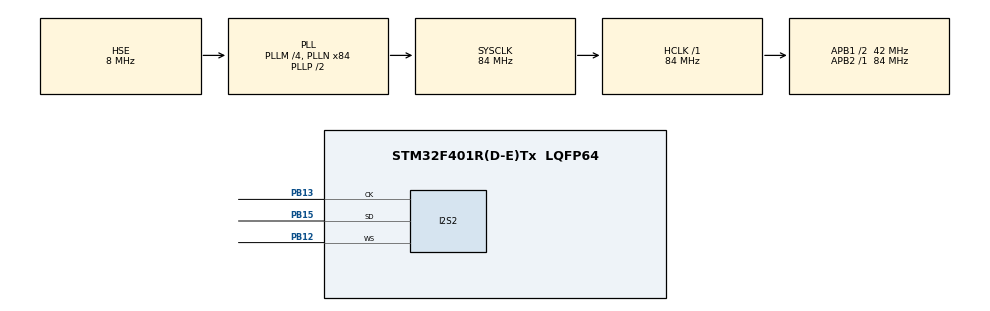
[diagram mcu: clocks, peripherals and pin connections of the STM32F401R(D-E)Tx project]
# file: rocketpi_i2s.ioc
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Dma.Request0=SPI2_TX
Dma.SPI2_TX.0.Direction=DMA_MEMORY_TO_PERIPH
Dma.SPI2_TX.0.FIFOMode=DMA_FIFOMODE_DISABLE
Dma.SPI2_TX.0.Instance=DMA1_Stream4
Dma.SPI2_TX.0.MemDataAlignment=DMA_MDATAALIGN_HALFWORD
Dma.SPI2_TX.0.MemInc=DMA_MINC_ENABLE
Dma.SPI2_TX.0.Mode=DMA_NORMAL
Dma.SPI2_TX.0.PeriphDataAlignment=DMA_PDATAALIGN_HALFWORD
Dma.SPI2_TX.0.PeriphInc=DMA_PINC_DISABLE
Dma.SPI2_TX.0.Priority=DMA_PRIORITY_LOW
I2S2.AudioFreq=I2S_AUDIOFREQ_16K
I2S2.DataFormat=I2S_DATAFORMAT_16B_EXTENDED
I2S2.ErrorAudioFreq=1.72 %
I2S2.FullDuplexMode=I2S_FULLDUPLEXMODE_DISABLE
I2S2.Instance=SPI$Index
I2S2.Mode=I2S_MODE_MASTER_TX
I2S2.RealAudioFreq=16.276 KHz
I2S2.VirtualMode=I2S_MODE_MASTER
Mcu.Family=STM32F4
Mcu.Name=STM32F401R(D-E)Tx
Mcu.Package=LQFP64
NVIC.DMA1_Stream4_IRQn=true\:0\:0\:false\:false\:true\:false\:true\:true
NVIC.PriorityGroup=NVIC_PRIORITYGROUP_4
NVIC.SPI2_IRQn=true\:0\:0\:false\:false\:true\:true\:true\:true
PA13.Mode=Serial_Wire
PA13.Signal=SYS_JTMS-SWDIO
PA14.Mode=Serial_Wire
PA14.Signal=SYS_JTCK-SWCLK
PB12.Mode=Half_Duplex_Master
PB12.Signal=I2S2_WS
PB13.Mode=Half_Duplex_Master
PB13.Signal=I2S2_CK
PB15.Mode=Half_Duplex_Master
PB15.Signal=I2S2_SD
PH0\ -\ OSC_IN.Mode=HSE-External-Oscillator
PH0\ -\ OSC_IN.Signal=RCC_OSC_IN
PH1\ -\ OSC_OUT.Mode=HSE-External-Oscillator
PH1\ -\ OSC_OUT.Signal=RCC_OSC_OUT
ProjectManager.HeapSize=0x200
ProjectManager.StackSize=0x400
ProjectManager.TargetToolchain=MDK-ARM V5.27
RCC.48MHZClocksFreq_Value=42000000
RCC.AHBFreq_Value=84000000
RCC.APB1CLKDivider=RCC_HCLK_DIV2
RCC.APB1Freq_Value=42000000
RCC.APB1TimFreq_Value=84000000
RCC.APB2Freq_Value=84000000
RCC.APB2TimFreq_Value=84000000
RCC.CortexFreq_Value=84000000
RCC.HCLKFreq_Value=84000000
RCC.HSE_VALUE=8000000
RCC.HSI_VALUE=16000000
RCC.LSE_VALUE=32768
RCC.PLLI2SN=50
RCC.PLLI2SR=4
RCC.PLLM=4
RCC.PLLN=84
RCC.PLLSourceVirtual=RCC_PLLSOURCE_HSE
RCC.SYSCLKFreq_VALUE=84000000
RCC.SYSCLKSource=RCC_SYSCLKSOURCE_PLLCLK
RCC.VCOOutputFreq_Value=168000000
board=custom

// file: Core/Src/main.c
/* USER CODE BEGIN Header */
/**
  ******************************************************************************
  * @file           : main.c
  * @brief          : Main program body
  ******************************************************************************
  * @attention
  *
  * Copyright (c) 2025 STMicroelectronics.
  * All rights reserved.
  *
  * This software is licensed under terms that can be found in the LICENSE file
  * in the root directory of this software component.
  * If no LICENSE file comes with this software, it is provided AS-IS.
  *
  ******************************************************************************
  */
/* USER CODE END Header */
#include "main.h"
#include "dma.h"
#include "i2s.h"
#include "gpio.h"

/* USER CODE BEGIN Includes */
#include "audio.h"
/* USER CODE END Includes */

/* USER CODE BEGIN PTD */
typedef enum
{
  AUDIO_PLAYBACK_STATE_IDLE = 0,
  AUDIO_PLAYBACK_STATE_RUNNING,
  AUDIO_PLAYBACK_STATE_DONE,
  AUDIO_PLAYBACK_STATE_ERROR
} audio_playback_state_t;

typedef struct
{
  uint32_t next_index;
  uint32_t samples_remaining;
  audio_playback_state_t state;
} audio_playback_ctrl_t;

/* USER CODE END PTD */

/* USER CODE BEGIN PD */
#define AUDIO_DMA_MAX_TRANSFER_SAMPLES 65535U

/* USER CODE END PD */

/* USER CODE BEGIN PV */
static volatile audio_playback_ctrl_t audio_ctrl = {0};

/* USER CODE END PV */

void SystemClock_Config(void);
/* USER CODE BEGIN PFP */
static HAL_StatusTypeDef Audio_StartNextChunk(void);
static void Audio_BeginPlayback(void);

/* USER CODE END PFP */

/* USER CODE BEGIN 0 */
static HAL_StatusTypeDef Audio_StartNextChunk(void)
{
  if (audio_ctrl.samples_remaining == 0U)
  {
    audio_ctrl.state = AUDIO_PLAYBACK_STATE_DONE;
    return HAL_OK;
  }

  uint32_t chunk = (audio_ctrl.samples_remaining > AUDIO_DMA_MAX_TRANSFER_SAMPLES) ?
                   AUDIO_DMA_MAX_TRANSFER_SAMPLES :
                   audio_ctrl.samples_remaining;

  const uint16_t *chunk_ptr = (const uint16_t *)&audio_track[audio_ctrl.next_index];
  HAL_StatusTypeDef status = HAL_I2S_Transmit_DMA(&hi2s2,
                                                  (uint16_t *)chunk_ptr,
                                                  (uint16_t)chunk);

  if (status == HAL_OK)
  {
    audio_ctrl.next_index += chunk;
    audio_ctrl.samples_remaining -= chunk;
    audio_ctrl.state = AUDIO_PLAYBACK_STATE_RUNNING;
  }

  return status;
}

static void Audio_BeginPlayback(void)
{
  audio_ctrl.next_index = 0U;
  audio_ctrl.samples_remaining = (uint32_t)AUDIO_TRACK_SAMPLE_COUNT;
  audio_ctrl.state = AUDIO_PLAYBACK_STATE_IDLE;

  if (audio_ctrl.samples_remaining == 0U)
  {
    audio_ctrl.state = AUDIO_PLAYBACK_STATE_DONE;
    return;
  }

  if (Audio_StartNextChunk() != HAL_OK)
  {
    audio_ctrl.state = AUDIO_PLAYBACK_STATE_ERROR;
    Error_Handler();
  }
}

/* USER CODE END 0 */

int main(void)
{

  /* MCU Configuration--------------------------------------------------------*/

  /* Reset of all peripherals, Initializes the Flash interface and the Systick. */
  HAL_Init();

  /* Configure the system clock */
  SystemClock_Config();

  /* Initialize all configured peripherals */
  MX_GPIO_Init();
  MX_DMA_Init();
  MX_I2S2_Init();
  /* USER CODE BEGIN 2 */
  Audio_BeginPlayback();

  /* USER CODE END 2 */

  /* Infinite loop */
  while (1)
  {

  }
}

void SystemClock_Config(void)
{
  RCC_OscInitTypeDef RCC_OscInitStruct = {0};
  RCC_ClkInitTypeDef RCC_ClkInitStruct = {0};

  /** Configure the main internal regulator output voltage
  */
  __HAL_RCC_PWR_CLK_ENABLE();
  __HAL_PWR_VOLTAGESCALING_CONFIG(PWR_REGULATOR_VOLTAGE_SCALE2);

  /** Initializes the RCC Oscillators according to the specified parameters
  * in the RCC_OscInitTypeDef structure.
  */
  RCC_OscInitStruct.OscillatorType = RCC_OSCILLATORTYPE_HSE;
  RCC_OscInitStruct.HSEState = RCC_HSE_ON;
  RCC_OscInitStruct.PLL.PLLState = RCC_PLL_ON;
  RCC_OscInitStruct.PLL.PLLSource = RCC_PLLSOURCE_HSE;
  RCC_OscInitStruct.PLL.PLLM = 4;
  RCC_OscInitStruct.PLL.PLLN = 84;
  RCC_OscInitStruct.PLL.PLLP = RCC_PLLP_DIV2;
  RCC_OscInitStruct.PLL.PLLQ = 4;
  if (HAL_RCC_OscConfig(&RCC_OscInitStruct) != HAL_OK)
  {
    Error_Handler();
  }

  /** Initializes the CPU, AHB and APB buses clocks
  */
  RCC_ClkInitStruct.ClockType = RCC_CLOCKTYPE_HCLK|RCC_CLOCKTYPE_SYSCLK
                              |RCC_CLOCKTYPE_PCLK1|RCC_CLOCKTYPE_PCLK2;
  RCC_ClkInitStruct.SYSCLKSource = RCC_SYSCLKSOURCE_PLLCLK;
  RCC_ClkInitStruct.AHBCLKDivider = RCC_SYSCLK_DIV1;
  RCC_ClkInitStruct.APB1CLKDivider = RCC_HCLK_DIV2;
  RCC_ClkInitStruct.APB2CLKDivider = RCC_HCLK_DIV1;

  if (HAL_RCC_ClockConfig(&RCC_ClkInitStruct, FLASH_LATENCY_2) != HAL_OK)
  {
    Error_Handler();
  }
}

/* USER CODE BEGIN 4 */
void HAL_I2S_TxCpltCallback(I2S_HandleTypeDef *hi2s)
{
  if (hi2s->Instance != hi2s2.Instance)
  {
    return;
  }

  if (audio_ctrl.samples_remaining == 0U)
  {
    audio_ctrl.state = AUDIO_PLAYBACK_STATE_DONE;
    return;
  }

  if (Audio_StartNextChunk() != HAL_OK)
  {
    audio_ctrl.state = AUDIO_PLAYBACK_STATE_ERROR;
    Error_Handler();
  }
}

void HAL_I2S_ErrorCallback(I2S_HandleTypeDef *hi2s)
{
  if (hi2s->Instance != hi2s2.Instance)
  {
    return;
  }

  audio_ctrl.state = AUDIO_PLAYBACK_STATE_ERROR;
  Error_Handler();
}

/* USER CODE END 4 */

void Error_Handler(void)
{
  __disable_irq();
  while (1)
  {
  }
}
